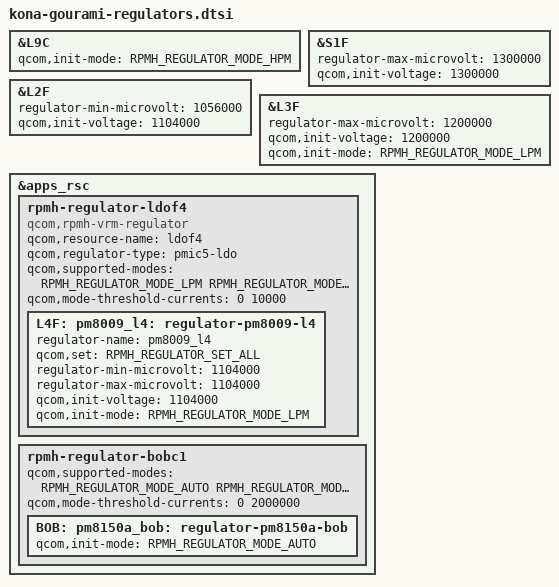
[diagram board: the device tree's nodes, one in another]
// SPDX-License-Identifier: GPL-2.0
/* Copyright (c) 2022, The Linux Foundation. All rights reserved.
 *
 * This program is free software; you can redistribute it and/or modify
 * it under the terms of the GNU General Public License version 2 and
 * only version 2 as published by the Free Software Foundation.
 *
 * This program is distributed in the hope that it will be useful,
 * but WITHOUT ANY WARRANTY; without even the implied warranty of
 * MERCHANTABILITY or FITNESS FOR A PARTICULAR PURPOSE.  See the
 * GNU General Public License for more details.
 */

#include <dt-bindings/regulator/qcom,rpmh-regulator-levels.h>

&L9C {
    qcom,init-mode = <RPMH_REGULATOR_MODE_HPM>;
};

&S1F {
	regulator-max-microvolt = <1300000>;
	qcom,init-voltage = <1300000>;
};

&L2F {
    regulator-min-microvolt = <1056000>;
    qcom,init-voltage = <1104000>;
};

&L3F {
    regulator-max-microvolt = <1200000>;
	qcom,init-voltage = <1200000>;
	qcom,init-mode = <RPMH_REGULATOR_MODE_LPM>;
};

/* RPMh regulators */
&apps_rsc {
    	rpmh-regulator-ldof4 {
		compatible = "qcom,rpmh-vrm-regulator";
		qcom,resource-name = "ldof4";
		qcom,regulator-type = "pmic5-ldo";
		qcom,supported-modes =
			<RPMH_REGULATOR_MODE_LPM
			 RPMH_REGULATOR_MODE_HPM>;
		qcom,mode-threshold-currents = <0 10000>;
		L4F: pm8009_l4: regulator-pm8009-l4 {
			regulator-name = "pm8009_l4";
			qcom,set = <RPMH_REGULATOR_SET_ALL>;
			regulator-min-microvolt = <1104000>;
			regulator-max-microvolt = <1104000>;
			qcom,init-voltage = <1104000>;
			qcom,init-mode = <RPMH_REGULATOR_MODE_LPM>;
		};
	};

	rpmh-regulator-bobc1 {
		qcom,supported-modes =
			<RPMH_REGULATOR_MODE_AUTO
			RPMH_REGULATOR_MODE_HPM>;
		qcom,mode-threshold-currents = <0 2000000>;

		BOB: pm8150a_bob: regulator-pm8150a-bob {
			qcom,init-mode = <RPMH_REGULATOR_MODE_AUTO>;
		};
	};
};
